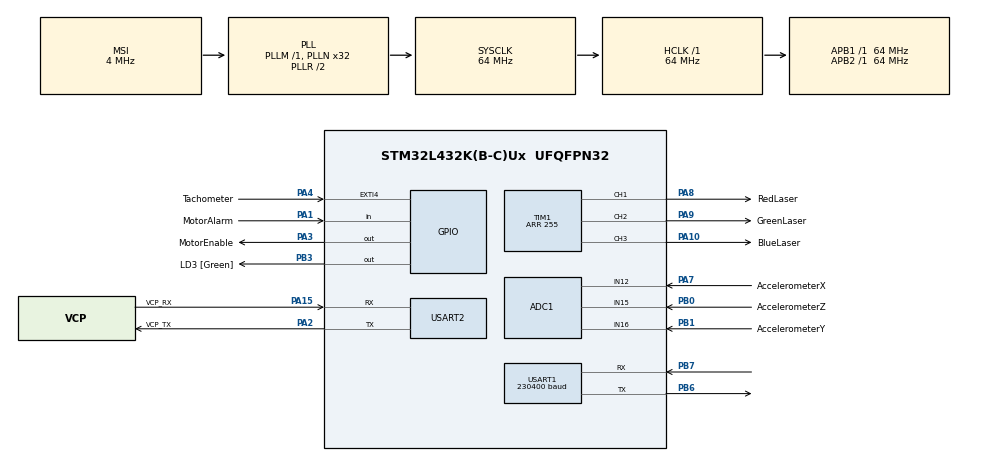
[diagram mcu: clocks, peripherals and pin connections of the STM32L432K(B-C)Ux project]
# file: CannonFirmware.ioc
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ADC1.Channel-3\#ChannelRegularConversion=ADC_CHANNEL_12
ADC1.NbrOfConversionFlag=1
ADC1.OffsetNumber-3\#ChannelRegularConversion=ADC_OFFSET_NONE
ADC1.Rank-3\#ChannelRegularConversion=1
ADC1.SamplingTime-3\#ChannelRegularConversion=ADC_SAMPLETIME_2CYCLES_5
ADC1.master=1
Dma.Request0=USART1_RX
Dma.Request1=USART1_TX
Dma.USART1_RX.0.Direction=DMA_PERIPH_TO_MEMORY
Dma.USART1_RX.0.Instance=DMA1_Channel5
Dma.USART1_RX.0.MemDataAlignment=DMA_MDATAALIGN_BYTE
Dma.USART1_RX.0.MemInc=DMA_MINC_ENABLE
Dma.USART1_RX.0.Mode=DMA_CIRCULAR
Dma.USART1_RX.0.PeriphDataAlignment=DMA_PDATAALIGN_BYTE
Dma.USART1_RX.0.PeriphInc=DMA_PINC_DISABLE
Dma.USART1_RX.0.Priority=DMA_PRIORITY_LOW
Dma.USART1_TX.1.Direction=DMA_MEMORY_TO_PERIPH
Dma.USART1_TX.1.Instance=DMA1_Channel4
Dma.USART1_TX.1.MemDataAlignment=DMA_MDATAALIGN_BYTE
Dma.USART1_TX.1.MemInc=DMA_MINC_ENABLE
Dma.USART1_TX.1.Mode=DMA_NORMAL
Dma.USART1_TX.1.PeriphDataAlignment=DMA_PDATAALIGN_BYTE
Dma.USART1_TX.1.PeriphInc=DMA_PINC_DISABLE
Dma.USART1_TX.1.Priority=DMA_PRIORITY_LOW
Mcu.Family=STM32L4
Mcu.Name=STM32L432K(B-C)Ux
Mcu.Package=UFQFPN32
NVIC.DMA1_Channel4_IRQn=true\:0\:0\:false\:false\:true\:false\:true\:true
NVIC.DMA1_Channel5_IRQn=true\:0\:0\:false\:false\:true\:false\:true\:true
NVIC.EXTI4_IRQn=true\:3\:0\:true\:false\:true\:true\:true\:true
NVIC.PriorityGroup=NVIC_PRIORITYGROUP_4
NVIC.TIM6_DAC_IRQn=true\:3\:0\:true\:false\:true\:true\:true\:true
NVIC.TIM7_IRQn=true\:1\:0\:true\:false\:true\:true\:true\:true
NVIC.USART1_IRQn=true\:4\:0\:true\:false\:true\:true\:true\:true
PA0.GPIO_Label=MCO [High speed clock in]
PA0.Mode=HSE-External-Clock-Source-for-LittleOrca
PA0.Signal=RCC_CK_IN
PA1.GPIO_Label=MotorAlarm
PA1.GPIO_PuPd=GPIO_PULLUP
PA1.Signal=GPIO_Input
PA10.GPIO_Label=BlueLaser
PA10.Signal=S_TIM1_CH3
PA13\ (JTMS-SWDIO).GPIO_Label=SWDIO
PA13\ (JTMS-SWDIO).Mode=Serial_Wire
PA13\ (JTMS-SWDIO).Signal=SYS_JTMS-SWDIO
PA14\ (JTCK-SWCLK).GPIO_Label=SWCLK
PA14\ (JTCK-SWCLK).Mode=Serial_Wire
PA14\ (JTCK-SWCLK).Signal=SYS_JTCK-SWCLK
PA15\ (JTDI).GPIO_Label=VCP_RX
PA15\ (JTDI).Mode=Asynchronous
PA15\ (JTDI).Signal=USART2_RX
PA2.GPIO_Label=VCP_TX
PA2.Mode=Asynchronous
PA2.Signal=USART2_TX
PA3.GPIO_Label=MotorEnable
PA3.GPIO_PuPd=GPIO_PULLDOWN
PA3.Signal=GPIO_Output
PA4.GPIO_Label=Tachometer
PA4.Signal=GPXTI4
PA7.GPIO_Label=AccelerometerX
PA7.Signal=ADCx_IN12
PA8.GPIO_Label=RedLaser
PA8.GPIO_PuPd=GPIO_NOPULL
PA8.GPIO_Speed=GPIO_SPEED_FREQ_LOW
PA8.Signal=S_TIM1_CH1
PA9.GPIO_Label=GreenLaser
PA9.Signal=S_TIM1_CH2
PB0.GPIO_Label=AccelerometerZ
PB0.Signal=ADCx_IN15
PB1.GPIO_Label=AccelerometerY
PB1.Signal=ADCx_IN16
PB3\ (JTDO-TRACESWO).GPIO_Label=LD3 [Green]
PB3\ (JTDO-TRACESWO).Signal=GPIO_Output
PB6.Mode=Asynchronous
PB6.Signal=USART1_TX
PB7.Mode=Asynchronous
PB7.Signal=USART1_RX
PC14-OSC32_IN\ (PC14).Mode=LSE-External-Oscillator
PC14-OSC32_IN\ (PC14).Signal=RCC_OSC32_IN
PC15-OSC32_OUT\ (PC15).Mode=LSE-External-Oscillator
PC15-OSC32_OUT\ (PC15).Signal=RCC_OSC32_OUT
ProjectManager.HeapSize=0x200
ProjectManager.StackSize=0x400
ProjectManager.TargetToolchain=STM32CubeIDE
RCC.ADCFreq_Value=32000000
RCC.AHBFreq_Value=64000000
RCC.APB1Freq_Value=64000000
RCC.APB1TimFreq_Value=64000000
RCC.APB2Freq_Value=64000000
RCC.APB2TimFreq_Value=64000000
RCC.CortexFreq_Value=64000000
RCC.HCLKFreq_Value=64000000
RCC.HSE_VALUE=8000000
RCC.HSI16_VALUE=16000000
RCC.HSI48_VALUE=48000000
RCC.HSI_VALUE=16000000
RCC.MSI_VALUE=4000000
RCC.PLLMUL=RCC_PLLMUL_4
RCC.PLLN=32
RCC.PLLSAI1N=16
RCC.SYSCLKFreq_VALUE=64000000
RCC.SYSCLKSource=RCC_SYSCLKSOURCE_PLLCLK
RCC.USBFreq_Value=32000000
RCC.VCOOutputFreq_Value=128000000
SH.ADCx_IN12.0=ADC1_IN12,IN12-Single-Ended
SH.ADCx_IN15.0=ADC1_IN15,IN15-Single-Ended
SH.ADCx_IN16.0=ADC1_IN16,IN16-Single-Ended
SH.S_TIM1_CH1.0=TIM1_CH1,PWM Generation1 CH1
SH.S_TIM1_CH2.0=TIM1_CH2,PWM Generation2 CH2
SH.S_TIM1_CH3.0=TIM1_CH3,PWM Generation3 CH3
TIM1.Channel-PWM\ Generation1\ CH1=TIM_CHANNEL_1
TIM1.Channel-PWM\ Generation2\ CH2=TIM_CHANNEL_2
TIM1.Channel-PWM\ Generation3\ CH3=TIM_CHANNEL_3
TIM1.Period=255
TIM6.AutoReloadPreload=TIM_AUTORELOAD_PRELOAD_ENABLE
TIM6.Period=12345
TIM6.Prescaler=0
TIM7.AutoReloadPreload=TIM_AUTORELOAD_PRELOAD_ENABLE
TIM7.Period=640
TIM7.Prescaler=999
USART1.BaudRate=230400
USART1.VirtualMode-Asynchronous=VM_ASYNC
USART2.VirtualMode-Asynchronous=VM_ASYNC
VP_TIM6_VS_ClockSourceINT.Mode=Enable_Timer
VP_TIM7_VS_ClockSourceINT.Mode=Enable_Timer
board=NUCLEO-L432KC

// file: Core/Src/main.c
/* USER CODE BEGIN Header */
/**
  ******************************************************************************
  * @file           : main.c
  * @brief          : Main program body
  ******************************************************************************
  * @attention
  *
  * Copyright (c) 2024 STMicroelectronics.
  * All rights reserved.
  *
  * This software is licensed under terms that can be found in the LICENSE file
  * in the root directory of this software component.
  * If no LICENSE file comes with this software, it is provided AS-IS.
  *
  ******************************************************************************
  */
/* USER CODE END Header */
#include "main.h"

/* USER CODE BEGIN Includes */
#include "CannonControl.h"
/* USER CODE END Includes */

ADC_HandleTypeDef hadc1;

TIM_HandleTypeDef htim1;
TIM_HandleTypeDef htim6;
TIM_HandleTypeDef htim7;

UART_HandleTypeDef huart1;
UART_HandleTypeDef huart2;
DMA_HandleTypeDef hdma_usart1_rx;
DMA_HandleTypeDef hdma_usart1_tx;

void SystemClock_Config(void);
static void MX_GPIO_Init(void);
static void MX_DMA_Init(void);
static void MX_USART2_UART_Init(void);
static void MX_TIM1_Init(void);
static void MX_TIM6_Init(void);
static void MX_USART1_UART_Init(void);
static void MX_TIM7_Init(void);
static void MX_ADC1_Init(void);

int main(void)
{

  /* MCU Configuration--------------------------------------------------------*/

  /* Reset of all peripherals, Initializes the Flash interface and the Systick. */
  HAL_Init();

  /* Configure the system clock */
  SystemClock_Config();

  /* Initialize all configured peripherals */
  MX_GPIO_Init();
  MX_DMA_Init();
  MX_USART2_UART_Init();
  MX_TIM1_Init();
  MX_TIM6_Init();
  MX_USART1_UART_Init();
  MX_TIM7_Init();
  MX_ADC1_Init();
  /* USER CODE BEGIN 2 */
  CannonControlInit();
  /* USER CODE END 2 */

  /* Infinite loop */
  /* USER CODE BEGIN WHILE */
  while (1)
  {
	CannonControlMain();
    /* USER CODE END WHILE */

  }
}

void SystemClock_Config(void)
{
  RCC_OscInitTypeDef RCC_OscInitStruct = {0};
  RCC_ClkInitTypeDef RCC_ClkInitStruct = {0};

  /** Configure the main internal regulator output voltage
  */
  if (HAL_PWREx_ControlVoltageScaling(PWR_REGULATOR_VOLTAGE_SCALE1) != HAL_OK)
  {
    Error_Handler();
  }

  /** Configure LSE Drive Capability
  */
  HAL_PWR_EnableBkUpAccess();
  __HAL_RCC_LSEDRIVE_CONFIG(RCC_LSEDRIVE_LOW);

  /** Initializes the RCC Oscillators according to the specified parameters
  * in the RCC_OscInitTypeDef structure.
  */
  RCC_OscInitStruct.OscillatorType = RCC_OSCILLATORTYPE_LSE|RCC_OSCILLATORTYPE_MSI;
  RCC_OscInitStruct.LSEState = RCC_LSE_ON;
  RCC_OscInitStruct.MSIState = RCC_MSI_ON;
  RCC_OscInitStruct.MSICalibrationValue = 0;
  RCC_OscInitStruct.MSIClockRange = RCC_MSIRANGE_6;
  RCC_OscInitStruct.PLL.PLLState = RCC_PLL_ON;
  RCC_OscInitStruct.PLL.PLLSource = RCC_PLLSOURCE_MSI;
  RCC_OscInitStruct.PLL.PLLM = 1;
  RCC_OscInitStruct.PLL.PLLN = 32;
  RCC_OscInitStruct.PLL.PLLP = RCC_PLLP_DIV7;
  RCC_OscInitStruct.PLL.PLLQ = RCC_PLLQ_DIV2;
  RCC_OscInitStruct.PLL.PLLR = RCC_PLLR_DIV2;
  if (HAL_RCC_OscConfig(&RCC_OscInitStruct) != HAL_OK)
  {
    Error_Handler();
  }

  /** Initializes the CPU, AHB and APB buses clocks
  */
  RCC_ClkInitStruct.ClockType = RCC_CLOCKTYPE_HCLK|RCC_CLOCKTYPE_SYSCLK
                              |RCC_CLOCKTYPE_PCLK1|RCC_CLOCKTYPE_PCLK2;
  RCC_ClkInitStruct.SYSCLKSource = RCC_SYSCLKSOURCE_PLLCLK;
  RCC_ClkInitStruct.AHBCLKDivider = RCC_SYSCLK_DIV1;
  RCC_ClkInitStruct.APB1CLKDivider = RCC_HCLK_DIV1;
  RCC_ClkInitStruct.APB2CLKDivider = RCC_HCLK_DIV1;

  if (HAL_RCC_ClockConfig(&RCC_ClkInitStruct, FLASH_LATENCY_3) != HAL_OK)
  {
    Error_Handler();
  }

  /** Enable MSI Auto calibration
  */
  HAL_RCCEx_EnableMSIPLLMode();
}

static void MX_ADC1_Init(void)
{

  ADC_ChannelConfTypeDef sConfig = {0};

  /** Common config
  */
  hadc1.Instance = ADC1;
  hadc1.Init.ClockPrescaler = ADC_CLOCK_ASYNC_DIV1;
  hadc1.Init.Resolution = ADC_RESOLUTION_12B;
  hadc1.Init.DataAlign = ADC_DATAALIGN_RIGHT;
  hadc1.Init.ScanConvMode = ADC_SCAN_DISABLE;
  hadc1.Init.EOCSelection = ADC_EOC_SINGLE_CONV;
  hadc1.Init.LowPowerAutoWait = DISABLE;
  hadc1.Init.ContinuousConvMode = DISABLE;
  hadc1.Init.NbrOfConversion = 1;
  hadc1.Init.DiscontinuousConvMode = DISABLE;
  hadc1.Init.ExternalTrigConv = ADC_SOFTWARE_START;
  hadc1.Init.ExternalTrigConvEdge = ADC_EXTERNALTRIGCONVEDGE_NONE;
  hadc1.Init.DMAContinuousRequests = DISABLE;
  hadc1.Init.Overrun = ADC_OVR_DATA_PRESERVED;
  hadc1.Init.OversamplingMode = DISABLE;
  if (HAL_ADC_Init(&hadc1) != HAL_OK)
  {
    Error_Handler();
  }

  /** Configure Regular Channel
  */
  sConfig.Channel = ADC_CHANNEL_12;
  sConfig.Rank = ADC_REGULAR_RANK_1;
  sConfig.SamplingTime = ADC_SAMPLETIME_2CYCLES_5;
  sConfig.SingleDiff = ADC_SINGLE_ENDED;
  sConfig.OffsetNumber = ADC_OFFSET_NONE;
  sConfig.Offset = 0;
  if (HAL_ADC_ConfigChannel(&hadc1, &sConfig) != HAL_OK)
  {
    Error_Handler();
  }

}

static void MX_TIM1_Init(void)
{

  TIM_MasterConfigTypeDef sMasterConfig = {0};
  TIM_OC_InitTypeDef sConfigOC = {0};
  TIM_BreakDeadTimeConfigTypeDef sBreakDeadTimeConfig = {0};

  htim1.Instance = TIM1;
  htim1.Init.Prescaler = 0;
  htim1.Init.CounterMode = TIM_COUNTERMODE_UP;
  htim1.Init.Period = 255;
  htim1.Init.ClockDivision = TIM_CLOCKDIVISION_DIV1;
  htim1.Init.RepetitionCounter = 0;
  htim1.Init.AutoReloadPreload = TIM_AUTORELOAD_PRELOAD_DISABLE;
  if (HAL_TIM_PWM_Init(&htim1) != HAL_OK)
  {
    Error_Handler();
  }
  sMasterConfig.MasterOutputTrigger = TIM_TRGO_RESET;
  sMasterConfig.MasterOutputTrigger2 = TIM_TRGO2_RESET;
  sMasterConfig.MasterSlaveMode = TIM_MASTERSLAVEMODE_DISABLE;
  if (HAL_TIMEx_MasterConfigSynchronization(&htim1, &sMasterConfig) != HAL_OK)
  {
    Error_Handler();
  }
  sConfigOC.OCMode = TIM_OCMODE_PWM1;
  sConfigOC.Pulse = 0;
  sConfigOC.OCPolarity = TIM_OCPOLARITY_HIGH;
  sConfigOC.OCNPolarity = TIM_OCNPOLARITY_HIGH;
  sConfigOC.OCFastMode = TIM_OCFAST_DISABLE;
  sConfigOC.OCIdleState = TIM_OCIDLESTATE_RESET;
  sConfigOC.OCNIdleState = TIM_OCNIDLESTATE_RESET;
  if (HAL_TIM_PWM_ConfigChannel(&htim1, &sConfigOC, TIM_CHANNEL_1) != HAL_OK)
  {
    Error_Handler();
  }
  if (HAL_TIM_PWM_ConfigChannel(&htim1, &sConfigOC, TIM_CHANNEL_2) != HAL_OK)
  {
    Error_Handler();
  }
  if (HAL_TIM_PWM_ConfigChannel(&htim1, &sConfigOC, TIM_CHANNEL_3) != HAL_OK)
  {
    Error_Handler();
  }
  sBreakDeadTimeConfig.OffStateRunMode = TIM_OSSR_DISABLE;
  sBreakDeadTimeConfig.OffStateIDLEMode = TIM_OSSI_DISABLE;
  sBreakDeadTimeConfig.LockLevel = TIM_LOCKLEVEL_OFF;
  sBreakDeadTimeConfig.DeadTime = 0;
  sBreakDeadTimeConfig.BreakState = TIM_BREAK_DISABLE;
  sBreakDeadTimeConfig.BreakPolarity = TIM_BREAKPOLARITY_HIGH;
  sBreakDeadTimeConfig.BreakFilter = 0;
  sBreakDeadTimeConfig.Break2State = TIM_BREAK2_DISABLE;
  sBreakDeadTimeConfig.Break2Polarity = TIM_BREAK2POLARITY_HIGH;
  sBreakDeadTimeConfig.Break2Filter = 0;
  sBreakDeadTimeConfig.AutomaticOutput = TIM_AUTOMATICOUTPUT_DISABLE;
  if (HAL_TIMEx_ConfigBreakDeadTime(&htim1, &sBreakDeadTimeConfig) != HAL_OK)
  {
    Error_Handler();
  }
  HAL_TIM_MspPostInit(&htim1);

}

static void MX_TIM6_Init(void)
{

  TIM_MasterConfigTypeDef sMasterConfig = {0};

  htim6.Instance = TIM6;
  htim6.Init.Prescaler = 0;
  htim6.Init.CounterMode = TIM_COUNTERMODE_UP;
  htim6.Init.Period = 12345;
  htim6.Init.AutoReloadPreload = TIM_AUTORELOAD_PRELOAD_ENABLE;
  if (HAL_TIM_Base_Init(&htim6) != HAL_OK)
  {
    Error_Handler();
  }
  sMasterConfig.MasterOutputTrigger = TIM_TRGO_RESET;
  sMasterConfig.MasterSlaveMode = TIM_MASTERSLAVEMODE_DISABLE;
  if (HAL_TIMEx_MasterConfigSynchronization(&htim6, &sMasterConfig) != HAL_OK)
  {
    Error_Handler();
  }

}

static void MX_TIM7_Init(void)
{

  TIM_MasterConfigTypeDef sMasterConfig = {0};

  htim7.Instance = TIM7;
  htim7.Init.Prescaler = 999;
  htim7.Init.CounterMode = TIM_COUNTERMODE_UP;
  htim7.Init.Period = 640;
  htim7.Init.AutoReloadPreload = TIM_AUTORELOAD_PRELOAD_ENABLE;
  if (HAL_TIM_Base_Init(&htim7) != HAL_OK)
  {
    Error_Handler();
  }
  sMasterConfig.MasterOutputTrigger = TIM_TRGO_RESET;
  sMasterConfig.MasterSlaveMode = TIM_MASTERSLAVEMODE_DISABLE;
  if (HAL_TIMEx_MasterConfigSynchronization(&htim7, &sMasterConfig) != HAL_OK)
  {
    Error_Handler();
  }

}

static void MX_USART1_UART_Init(void)
{

  huart1.Instance = USART1;
  huart1.Init.BaudRate = 230400;
  huart1.Init.WordLength = UART_WORDLENGTH_8B;
  huart1.Init.StopBits = UART_STOPBITS_1;
  huart1.Init.Parity = UART_PARITY_NONE;
  huart1.Init.Mode = UART_MODE_TX_RX;
  huart1.Init.HwFlowCtl = UART_HWCONTROL_NONE;
  huart1.Init.OverSampling = UART_OVERSAMPLING_16;
  huart1.Init.OneBitSampling = UART_ONE_BIT_SAMPLE_DISABLE;
  huart1.AdvancedInit.AdvFeatureInit = UART_ADVFEATURE_NO_INIT;
  if (HAL_UART_Init(&huart1) != HAL_OK)
  {
    Error_Handler();
  }

}

static void MX_USART2_UART_Init(void)
{

  huart2.Instance = USART2;
  huart2.Init.BaudRate = 115200;
  huart2.Init.WordLength = UART_WORDLENGTH_8B;
  huart2.Init.StopBits = UART_STOPBITS_1;
  huart2.Init.Parity = UART_PARITY_NONE;
  huart2.Init.Mode = UART_MODE_TX_RX;
  huart2.Init.HwFlowCtl = UART_HWCONTROL_NONE;
  huart2.Init.OverSampling = UART_OVERSAMPLING_16;
  huart2.Init.OneBitSampling = UART_ONE_BIT_SAMPLE_DISABLE;
  huart2.AdvancedInit.AdvFeatureInit = UART_ADVFEATURE_NO_INIT;
  if (HAL_UART_Init(&huart2) != HAL_OK)
  {
    Error_Handler();
  }

}

static void MX_DMA_Init(void)
{

  /* DMA controller clock enable */
  __HAL_RCC_DMA1_CLK_ENABLE();

  /* DMA interrupt init */
  /* DMA1_Channel4_IRQn interrupt configuration */
  HAL_NVIC_SetPriority(DMA1_Channel4_IRQn, 0, 0);
  HAL_NVIC_EnableIRQ(DMA1_Channel4_IRQn);
  /* DMA1_Channel5_IRQn interrupt configuration */
  HAL_NVIC_SetPriority(DMA1_Channel5_IRQn, 0, 0);
  HAL_NVIC_EnableIRQ(DMA1_Channel5_IRQn);

}

static void MX_GPIO_Init(void)
{
  GPIO_InitTypeDef GPIO_InitStruct = {0};

  /* GPIO Ports Clock Enable */
  __HAL_RCC_GPIOC_CLK_ENABLE();
  __HAL_RCC_GPIOA_CLK_ENABLE();
  __HAL_RCC_GPIOB_CLK_ENABLE();

  /*Configure GPIO pin Output Level */
  HAL_GPIO_WritePin(MotorEnable_GPIO_Port, MotorEnable_Pin, GPIO_PIN_RESET);

  /*Configure GPIO pin Output Level */
  HAL_GPIO_WritePin(LD3_GPIO_Port, LD3_Pin, GPIO_PIN_RESET);

  /*Configure GPIO pin : MotorAlarm_Pin */
  GPIO_InitStruct.Pin = MotorAlarm_Pin;
  GPIO_InitStruct.Mode = GPIO_MODE_INPUT;
  GPIO_InitStruct.Pull = GPIO_PULLUP;
  HAL_GPIO_Init(MotorAlarm_GPIO_Port, &GPIO_InitStruct);

  /*Configure GPIO pin : MotorEnable_Pin */
  GPIO_InitStruct.Pin = MotorEnable_Pin;
  GPIO_InitStruct.Mode = GPIO_MODE_OUTPUT_PP;
  GPIO_InitStruct.Pull = GPIO_PULLDOWN;
  GPIO_InitStruct.Speed = GPIO_SPEED_FREQ_LOW;
  HAL_GPIO_Init(MotorEnable_GPIO_Port, &GPIO_InitStruct);

  /*Configure GPIO pin : Tachometer_Pin */
  GPIO_InitStruct.Pin = Tachometer_Pin;
  GPIO_InitStruct.Mode = GPIO_MODE_IT_RISING;
  GPIO_InitStruct.Pull = GPIO_NOPULL;
  HAL_GPIO_Init(Tachometer_GPIO_Port, &GPIO_InitStruct);

  /*Configure GPIO pin : LD3_Pin */
  GPIO_InitStruct.Pin = LD3_Pin;
  GPIO_InitStruct.Mode = GPIO_MODE_OUTPUT_PP;
  GPIO_InitStruct.Pull = GPIO_NOPULL;
  GPIO_InitStruct.Speed = GPIO_SPEED_FREQ_LOW;
  HAL_GPIO_Init(LD3_GPIO_Port, &GPIO_InitStruct);

  /* EXTI interrupt init*/
  HAL_NVIC_SetPriority(EXTI4_IRQn, 3, 0);
  HAL_NVIC_EnableIRQ(EXTI4_IRQn);

}

void Error_Handler(void)
{
  __disable_irq();
  while (1)
  {
  }
}
